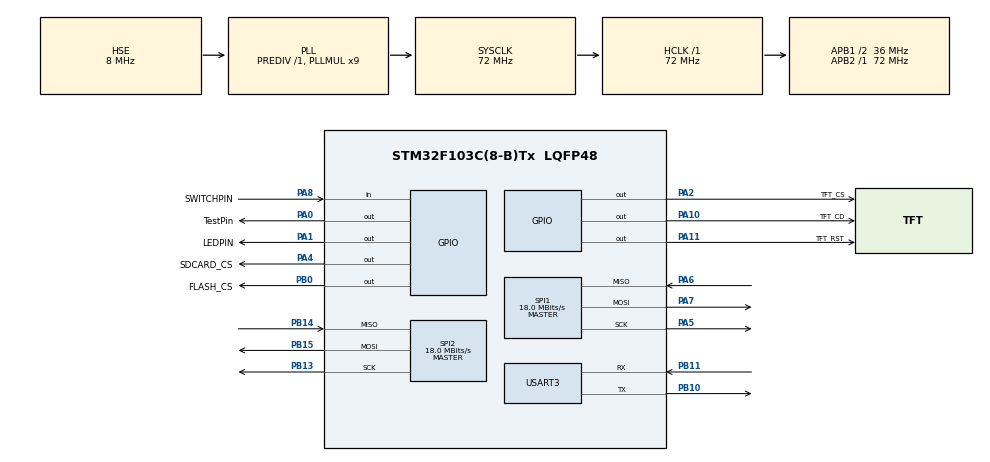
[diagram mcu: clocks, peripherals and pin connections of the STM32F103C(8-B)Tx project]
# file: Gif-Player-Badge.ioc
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Dma.Request0=SPI1_TX
Dma.SPI1_TX.0.Direction=DMA_MEMORY_TO_PERIPH
Dma.SPI1_TX.0.Instance=DMA1_Channel3
Dma.SPI1_TX.0.MemDataAlignment=DMA_MDATAALIGN_BYTE
Dma.SPI1_TX.0.MemInc=DMA_MINC_ENABLE
Dma.SPI1_TX.0.Mode=DMA_CIRCULAR
Dma.SPI1_TX.0.PeriphDataAlignment=DMA_PDATAALIGN_BYTE
Dma.SPI1_TX.0.PeriphInc=DMA_PINC_DISABLE
Dma.SPI1_TX.0.Priority=DMA_PRIORITY_VERY_HIGH
Mcu.Family=STM32F1
Mcu.Name=STM32F103C(8-B)Tx
Mcu.Package=LQFP48
NVIC.DMA1_Channel3_IRQn=true\:0\:0\:false\:false\:true\:false\:true
NVIC.PriorityGroup=NVIC_PRIORITYGROUP_4
PA0-WKUP.GPIO_Label=TestPin
PA0-WKUP.Signal=GPIO_Output
PA1.GPIO_Label=LEDPIN
PA1.Signal=GPIO_Output
PA10.GPIO_Label=TFT_CD
PA10.Signal=GPIO_Output
PA11.GPIO_Label=TFT_RST
PA11.Signal=GPIO_Output
PA13.Mode=Serial_Wire
PA13.Signal=SYS_JTMS-SWDIO
PA14.Mode=Serial_Wire
PA14.Signal=SYS_JTCK-SWCLK
PA2.GPIO_Label=TFT_CS
PA2.Signal=GPIO_Output
PA4.GPIO_Label=SDCARD_CS
PA4.Signal=GPIO_Output
PA5.Mode=Full_Duplex_Master
PA5.Signal=SPI1_SCK
PA6.Mode=Full_Duplex_Master
PA6.Signal=SPI1_MISO
PA7.Mode=Full_Duplex_Master
PA7.Signal=SPI1_MOSI
PA8.GPIO_Label=SWITCHPIN
PA8.Signal=GPIO_Input
PB0.GPIO_Label=FLASH_CS
PB0.Signal=GPIO_Output
PB10.Mode=Asynchronous
PB10.Signal=USART3_TX
PB11.Mode=Asynchronous
PB11.Signal=USART3_RX
PB13.Mode=Full_Duplex_Master
PB13.Signal=SPI2_SCK
PB14.Mode=Full_Duplex_Master
PB14.Signal=SPI2_MISO
PB15.Mode=Full_Duplex_Master
PB15.Signal=SPI2_MOSI
PD0-OSC_IN.Mode=HSE-External-Oscillator
PD0-OSC_IN.Signal=RCC_OSC_IN
PD1-OSC_OUT.Mode=HSE-External-Oscillator
PD1-OSC_OUT.Signal=RCC_OSC_OUT
ProjectManager.HeapSize=0x200
ProjectManager.StackSize=0x400
ProjectManager.TargetToolchain=STM32CubeIDE
RCC.AHBFreq_Value=72000000
RCC.APB1CLKDivider=RCC_HCLK_DIV2
RCC.APB1Freq_Value=36000000
RCC.APB1TimFreq_Value=72000000
RCC.APB2Freq_Value=72000000
RCC.APB2TimFreq_Value=72000000
RCC.HCLKFreq_Value=72000000
RCC.PLLMUL=RCC_PLL_MUL9
RCC.PLLSourceVirtual=RCC_PLLSOURCE_HSE
RCC.SYSCLKFreq_VALUE=72000000
RCC.SYSCLKSource=RCC_SYSCLKSOURCE_PLLCLK
RCC.USBFreq_Value=72000000
SPI1.BaudRatePrescaler=SPI_BAUDRATEPRESCALER_4
SPI1.CalculateBaudRate=18.0 MBits/s
SPI1.Direction=SPI_DIRECTION_2LINES
SPI1.Mode=SPI_MODE_MASTER
SPI1.VirtualType=VM_MASTER
SPI2.BaudRatePrescaler=SPI_BAUDRATEPRESCALER_2
SPI2.CalculateBaudRate=18.0 MBits/s
SPI2.Direction=SPI_DIRECTION_2LINES
SPI2.Mode=SPI_MODE_MASTER
SPI2.VirtualType=VM_MASTER
USART3.VirtualMode=VM_ASYNC
board=custom

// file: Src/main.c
/* USER CODE BEGIN Header */
/**
  ******************************************************************************
  * @file           : main.c
  * @brief          : Main program body
  ******************************************************************************
  * @attention
  *
  * <h2><center>&copy; Copyright (c) 2019 STMicroelectronics.
  * All rights reserved.</center></h2>
  *
  * This software component is licensed by ST under BSD 3-Clause license,
  * the "License"; You may not use this file except in compliance with the
  * License. You may obtain a copy of the License at:
  *                        opensource.org/licenses/BSD-3-Clause
  *
  ******************************************************************************
  */
/* USER CODE END Header */

#include "main.h"

SPI_HandleTypeDef hspi1;
SPI_HandleTypeDef hspi2;
DMA_HandleTypeDef hdma_spi1_tx;

UART_HandleTypeDef huart3;

void SystemClock_Config(void);
static void MX_GPIO_Init(void);
static void MX_DMA_Init(void);
static void MX_SPI1_Init(void);
static void MX_SPI2_Init(void);
static void MX_USART3_UART_Init(void);

int main(void)
{

  /* MCU Configuration--------------------------------------------------------*/

  /* Reset of all peripherals, Initializes the Flash interface and the Systick. */
  HAL_Init();

  /* Configure the system clock */
  SystemClock_Config();

  /* Initialize all configured peripherals */
  MX_GPIO_Init();
  MX_DMA_Init();
  MX_SPI1_Init();
  MX_SPI2_Init();
  MX_USART3_UART_Init();

  /* Infinite loop */
  /* USER CODE BEGIN WHILE */
  LCD_init();
  LCD_Fill_Screen(0xFFFF);
  HAL_Delay(250);
  while (1)
  {
    /* USER CODE END WHILE */

  }
}

void SystemClock_Config(void)
{
  RCC_OscInitTypeDef RCC_OscInitStruct = {0};
  RCC_ClkInitTypeDef RCC_ClkInitStruct = {0};

  /** Initializes the CPU, AHB and APB busses clocks
  */
  RCC_OscInitStruct.OscillatorType = RCC_OSCILLATORTYPE_HSE;
  RCC_OscInitStruct.HSEState = RCC_HSE_ON;
  RCC_OscInitStruct.HSEPredivValue = RCC_HSE_PREDIV_DIV1;
  RCC_OscInitStruct.HSIState = RCC_HSI_ON;
  RCC_OscInitStruct.PLL.PLLState = RCC_PLL_ON;
  RCC_OscInitStruct.PLL.PLLSource = RCC_PLLSOURCE_HSE;
  RCC_OscInitStruct.PLL.PLLMUL = RCC_PLL_MUL9;
  if (HAL_RCC_OscConfig(&RCC_OscInitStruct) != HAL_OK)
  {
    Error_Handler();
  }
  /** Initializes the CPU, AHB and APB busses clocks
  */
  RCC_ClkInitStruct.ClockType = RCC_CLOCKTYPE_HCLK|RCC_CLOCKTYPE_SYSCLK
                              |RCC_CLOCKTYPE_PCLK1|RCC_CLOCKTYPE_PCLK2;
  RCC_ClkInitStruct.SYSCLKSource = RCC_SYSCLKSOURCE_PLLCLK;
  RCC_ClkInitStruct.AHBCLKDivider = RCC_SYSCLK_DIV1;
  RCC_ClkInitStruct.APB1CLKDivider = RCC_HCLK_DIV2;
  RCC_ClkInitStruct.APB2CLKDivider = RCC_HCLK_DIV1;

  if (HAL_RCC_ClockConfig(&RCC_ClkInitStruct, FLASH_LATENCY_2) != HAL_OK)
  {
    Error_Handler();
  }
}

static void MX_SPI1_Init(void)
{

  /* SPI1 parameter configuration*/
  hspi1.Instance = SPI1;
  hspi1.Init.Mode = SPI_MODE_MASTER;
  hspi1.Init.Direction = SPI_DIRECTION_2LINES;
  hspi1.Init.DataSize = SPI_DATASIZE_8BIT;
  hspi1.Init.CLKPolarity = SPI_POLARITY_LOW;
  hspi1.Init.CLKPhase = SPI_PHASE_1EDGE;
  hspi1.Init.NSS = SPI_NSS_SOFT;
  hspi1.Init.BaudRatePrescaler = SPI_BAUDRATEPRESCALER_4;
  hspi1.Init.FirstBit = SPI_FIRSTBIT_MSB;
  hspi1.Init.TIMode = SPI_TIMODE_DISABLE;
  hspi1.Init.CRCCalculation = SPI_CRCCALCULATION_DISABLE;
  hspi1.Init.CRCPolynomial = 10;
  if (HAL_SPI_Init(&hspi1) != HAL_OK)
  {
    Error_Handler();
  }

}

static void MX_SPI2_Init(void)
{

  /* SPI2 parameter configuration*/
  hspi2.Instance = SPI2;
  hspi2.Init.Mode = SPI_MODE_MASTER;
  hspi2.Init.Direction = SPI_DIRECTION_2LINES;
  hspi2.Init.DataSize = SPI_DATASIZE_8BIT;
  hspi2.Init.CLKPolarity = SPI_POLARITY_LOW;
  hspi2.Init.CLKPhase = SPI_PHASE_1EDGE;
  hspi2.Init.NSS = SPI_NSS_SOFT;
  hspi2.Init.BaudRatePrescaler = SPI_BAUDRATEPRESCALER_2;
  hspi2.Init.FirstBit = SPI_FIRSTBIT_MSB;
  hspi2.Init.TIMode = SPI_TIMODE_DISABLE;
  hspi2.Init.CRCCalculation = SPI_CRCCALCULATION_DISABLE;
  hspi2.Init.CRCPolynomial = 10;
  if (HAL_SPI_Init(&hspi2) != HAL_OK)
  {
    Error_Handler();
  }

}

static void MX_USART3_UART_Init(void)
{

  huart3.Instance = USART3;
  huart3.Init.BaudRate = 115200;
  huart3.Init.WordLength = UART_WORDLENGTH_8B;
  huart3.Init.StopBits = UART_STOPBITS_1;
  huart3.Init.Parity = UART_PARITY_NONE;
  huart3.Init.Mode = UART_MODE_TX_RX;
  huart3.Init.HwFlowCtl = UART_HWCONTROL_NONE;
  huart3.Init.OverSampling = UART_OVERSAMPLING_16;
  if (HAL_UART_Init(&huart3) != HAL_OK)
  {
    Error_Handler();
  }

}

static void MX_DMA_Init(void)
{

  /* DMA controller clock enable */
  __HAL_RCC_DMA1_CLK_ENABLE();

  /* DMA interrupt init */
  /* DMA1_Channel3_IRQn interrupt configuration */
  HAL_NVIC_SetPriority(DMA1_Channel3_IRQn, 0, 0);
  HAL_NVIC_EnableIRQ(DMA1_Channel3_IRQn);

}

static void MX_GPIO_Init(void)
{
  GPIO_InitTypeDef GPIO_InitStruct = {0};

  /* GPIO Ports Clock Enable */
  __HAL_RCC_GPIOD_CLK_ENABLE();
  __HAL_RCC_GPIOA_CLK_ENABLE();
  __HAL_RCC_GPIOB_CLK_ENABLE();

  /*Configure GPIO pin Output Level */
  HAL_GPIO_WritePin(GPIOA, TestPin_Pin|LEDPIN_Pin|TFT_CS_Pin|SDCARD_CS_Pin
                          |TFT_CD_Pin|TFT_RST_Pin, GPIO_PIN_RESET);

  /*Configure GPIO pin Output Level */
  HAL_GPIO_WritePin(FLASH_CS_GPIO_Port, FLASH_CS_Pin, GPIO_PIN_RESET);

  /*Configure GPIO pins : TestPin_Pin LEDPIN_Pin TFT_CS_Pin SDCARD_CS_Pin
                           TFT_CD_Pin TFT_RST_Pin */
  GPIO_InitStruct.Pin = TestPin_Pin|LEDPIN_Pin|TFT_CS_Pin|SDCARD_CS_Pin
                          |TFT_CD_Pin|TFT_RST_Pin;
  GPIO_InitStruct.Mode = GPIO_MODE_OUTPUT_PP;
  GPIO_InitStruct.Pull = GPIO_NOPULL;
  GPIO_InitStruct.Speed = GPIO_SPEED_FREQ_LOW;
  HAL_GPIO_Init(GPIOA, &GPIO_InitStruct);

  /*Configure GPIO pin : FLASH_CS_Pin */
  GPIO_InitStruct.Pin = FLASH_CS_Pin;
  GPIO_InitStruct.Mode = GPIO_MODE_OUTPUT_PP;
  GPIO_InitStruct.Pull = GPIO_NOPULL;
  GPIO_InitStruct.Speed = GPIO_SPEED_FREQ_LOW;
  HAL_GPIO_Init(FLASH_CS_GPIO_Port, &GPIO_InitStruct);

  /*Configure GPIO pin : SWITCHPIN_Pin */
  GPIO_InitStruct.Pin = SWITCHPIN_Pin;
  GPIO_InitStruct.Mode = GPIO_MODE_INPUT;
  GPIO_InitStruct.Pull = GPIO_NOPULL;
  HAL_GPIO_Init(SWITCHPIN_GPIO_Port, &GPIO_InitStruct);

}

void Error_Handler(void)
{
}

/************************ (C) COPYRIGHT STMicroelectronics *****END OF FILE****/
